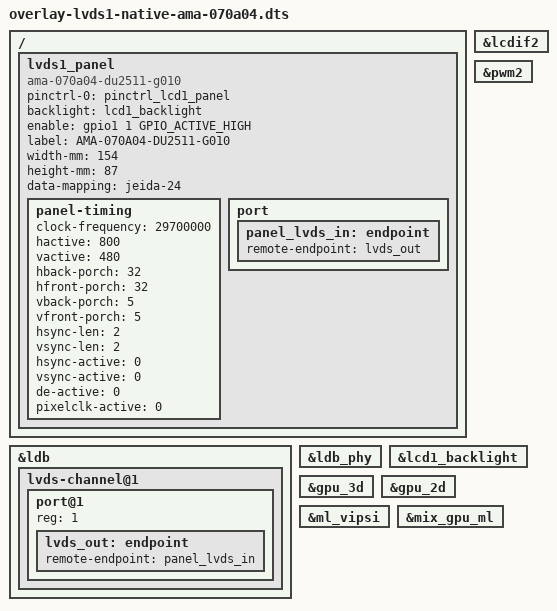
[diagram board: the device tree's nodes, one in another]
/*
 * Copyright (C) 2022 Avnet Embedded GmbH
 *
 * This program is free software; you can redistribute it and/or
 * modify it under the terms of the GNU General Public License as
 * published by the Free Software Foundation version 2.
 *
 * This program is distributed "as is" WITHOUT ANY WARRANTY of any
 * kind, whether express or implied; without even the implied warranty
 * of MERCHANTABILITY or FITNESS FOR A PARTICULAR PURPOSE.  See the
 * GNU General Public License for more details.
 */

/dts-v1/;
/plugin/;

#include <dt-bindings/gpio/gpio.h>

/ {
	fragment@4100 {
		target-path = "/";
		__overlay__ {
			lvds1_panel {
				pinctrl-names = "default";
				pinctrl-0 = <&pinctrl_lcd1_panel>;
				compatible = "ama-070a04-du2511-g010", "panel-lvds";
				backlight = <&lcd1_backlight>;
				enable =  <&gpio1 1 GPIO_ACTIVE_HIGH>;

				label = "AMA-070A04-DU2511-G010";
				width-mm = <154>;
				height-mm = <87>;
				data-mapping = "jeida-24";

				 panel-timing {
					clock-frequency = <29700000>;
					hactive = <800>;
					vactive = <480>;
					hback-porch = <32>;
					hfront-porch = <32>;
					vback-porch = <5>;
					vfront-porch = <5>;
					hsync-len = <2>;
					vsync-len = <2>;
					hsync-active = <0>;
					vsync-active = <0>;
					de-active = <0>;
					pixelclk-active = <0>;
				};

				port {
					panel_lvds_in: endpoint {
						remote-endpoint = <&lvds_out>;
					};
				};
			};
		};
	};

	fragment@4101 {
		target = <&lcdif2>;
		__overlay__ {
			status = "okay";
		};
	};

	fragment@4102 {
		target = <&ldb>;
		__overlay__ {
			status = "okay";

			lvds-channel@1 {
				#address-cells = <1>;
				#size-cells = <0>;
				status = "okay";

				port@1 {
					reg = <1>;

					lvds_out: endpoint {
						remote-endpoint = <&panel_lvds_in>;
					};
				};
			};
		};
	};

	fragment@4103 {
		target = <&ldb_phy>;
		__overlay__ {
			status = "okay";
		};
	};

	fragment@4104 {
		target = <&pwm2>;
		__overlay__ {
			status = "okay";
		};
	};

	fragment@4105 {
		target = <&lcd1_backlight>;
		__overlay__ {
			status = "okay";
		};
	};

	fragment@4106 {
		target = <&gpu_3d>;
		__overlay__ {
			status = "okay";
		};
	};

	fragment@4107 {
		target = <&gpu_2d>;
		__overlay__ {
			status = "okay";
		};
	};

	fragment@4108 {
		target = <&ml_vipsi>;
		__overlay__ {
			status = "okay";
		};
	};

	fragment@4109 {
		target = <&mix_gpu_ml>;
		__overlay__ {
			status = "okay";
		};
	};
};
